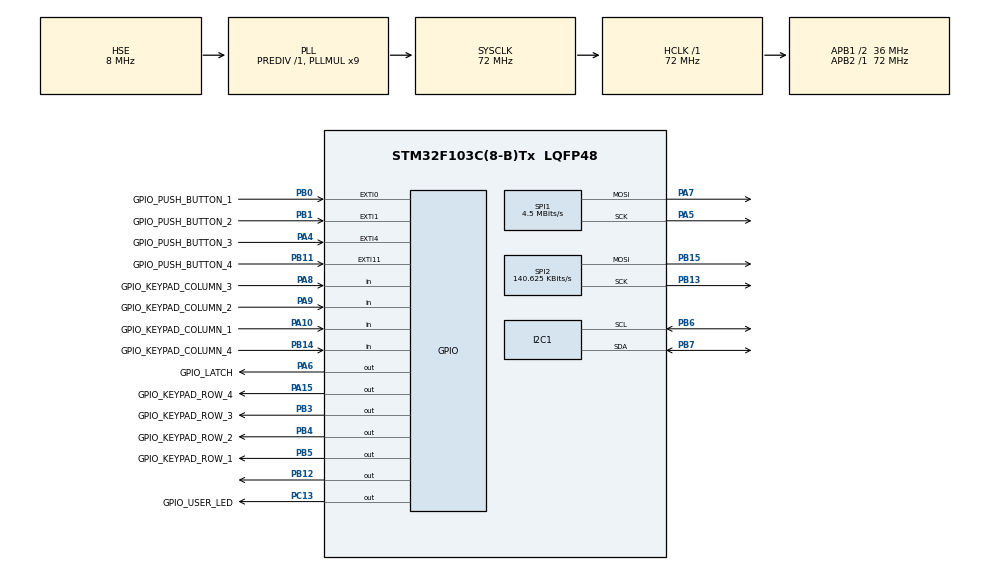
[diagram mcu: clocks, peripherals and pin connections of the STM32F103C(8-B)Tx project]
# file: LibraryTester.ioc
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I2C1.I2C_Mode=I2C_Standard
Mcu.Family=STM32F1
Mcu.Name=STM32F103C(8-B)Tx
Mcu.Package=LQFP48
NVIC.EXTI0_IRQn=true\:0\:0\:false\:false\:true\:true\:true
NVIC.EXTI15_10_IRQn=true\:0\:0\:false\:false\:true\:true\:true
NVIC.EXTI1_IRQn=true\:0\:0\:false\:false\:true\:true\:true
NVIC.EXTI4_IRQn=true\:0\:0\:false\:false\:true\:true\:true
NVIC.PriorityGroup=NVIC_PRIORITYGROUP_4
PA10.GPIO_Label=GPIO_KEYPAD_COLUMN_1
PA10.Signal=GPIO_Input
PA13.Mode=Serial_Wire
PA13.Signal=SYS_JTMS-SWDIO
PA14.Mode=Serial_Wire
PA14.Signal=SYS_JTCK-SWCLK
PA15.GPIO_Label=GPIO_KEYPAD_ROW_4
PA15.GPIO_Speed=GPIO_SPEED_FREQ_HIGH
PA15.Signal=GPIO_Output
PA4.GPIO_Label=GPIO_PUSH_BUTTON_3
PA4.GPIO_ModeDefaultEXTI=GPIO_MODE_IT_RISING_FALLING
PA4.Signal=GPXTI4
PA5.Mode=TX_Only_Simplex_Unidirect_Master
PA5.Signal=SPI1_SCK
PA6.GPIO_Label=GPIO_LATCH
PA6.Signal=GPIO_Output
PA7.Mode=TX_Only_Simplex_Unidirect_Master
PA7.Signal=SPI1_MOSI
PA8.GPIO_Label=GPIO_KEYPAD_COLUMN_3
PA8.Signal=GPIO_Input
PA9.GPIO_Label=GPIO_KEYPAD_COLUMN_2
PA9.Signal=GPIO_Input
PB0.GPIO_Label=GPIO_PUSH_BUTTON_1
PB0.GPIO_ModeDefaultEXTI=GPIO_MODE_IT_RISING_FALLING
PB0.GPIO_PuPd=GPIO_PULLDOWN
PB0.Signal=GPXTI0
PB1.GPIO_Label=GPIO_PUSH_BUTTON_2
PB1.GPIO_ModeDefaultEXTI=GPIO_MODE_IT_RISING_FALLING
PB1.GPIO_PuPd=GPIO_PULLDOWN
PB1.Signal=GPXTI1
PB11.GPIO_Label=GPIO_PUSH_BUTTON_4
PB11.GPIO_ModeDefaultEXTI=GPIO_MODE_IT_RISING_FALLING
PB11.GPIO_PuPd=GPIO_PULLDOWN
PB11.Signal=GPXTI11
PB12.Signal=GPIO_Output
PB13.Mode=TX_Only_Simplex_Unidirect_Master
PB13.Signal=SPI2_SCK
PB14.GPIO_Label=GPIO_KEYPAD_COLUMN_4
PB14.Signal=GPIO_Input
PB15.Mode=TX_Only_Simplex_Unidirect_Master
PB15.Signal=SPI2_MOSI
PB3.GPIO_Label=GPIO_KEYPAD_ROW_3
PB3.GPIO_Speed=GPIO_SPEED_FREQ_HIGH
PB3.Signal=GPIO_Output
PB4.GPIO_Label=GPIO_KEYPAD_ROW_2
PB4.GPIO_Speed=GPIO_SPEED_FREQ_HIGH
PB4.Signal=GPIO_Output
PB5.GPIO_Label=GPIO_KEYPAD_ROW_1
PB5.GPIO_Speed=GPIO_SPEED_FREQ_HIGH
PB5.Signal=GPIO_Output
PB6.Mode=I2C
PB6.Signal=I2C1_SCL
PB7.Mode=I2C
PB7.Signal=I2C1_SDA
PC13-TAMPER-RTC.GPIO_Label=GPIO_USER_LED
PC13-TAMPER-RTC.Signal=GPIO_Output
PD0-OSC_IN.Mode=HSE-External-Oscillator
PD0-OSC_IN.Signal=RCC_OSC_IN
PD1-OSC_OUT.Mode=HSE-External-Oscillator
PD1-OSC_OUT.Signal=RCC_OSC_OUT
ProjectManager.HeapSize=0x200
ProjectManager.StackSize=0x400
ProjectManager.TargetToolchain=STM32CubeIDE
RCC.AHBFreq_Value=72000000
RCC.APB1CLKDivider=RCC_HCLK_DIV2
RCC.APB1Freq_Value=36000000
RCC.APB1TimFreq_Value=72000000
RCC.APB2Freq_Value=72000000
RCC.APB2TimFreq_Value=72000000
RCC.HCLKFreq_Value=72000000
RCC.PLLMUL=RCC_PLL_MUL9
RCC.PLLSourceVirtual=RCC_PLLSOURCE_HSE
RCC.SYSCLKFreq_VALUE=72000000
RCC.SYSCLKSource=RCC_SYSCLKSOURCE_PLLCLK
RCC.USBFreq_Value=72000000
SPI1.BaudRatePrescaler=SPI_BAUDRATEPRESCALER_16
SPI1.CalculateBaudRate=4.5 MBits/s
SPI1.Direction=SPI_DIRECTION_2LINES
SPI1.Mode=SPI_MODE_MASTER
SPI1.VirtualType=VM_MASTER
SPI2.BaudRatePrescaler=SPI_BAUDRATEPRESCALER_256
SPI2.CalculateBaudRate=140.625 KBits/s
SPI2.Direction=SPI_DIRECTION_2LINES
SPI2.Mode=SPI_MODE_MASTER
SPI2.VirtualType=VM_MASTER
board=custom

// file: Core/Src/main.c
/* USER CODE BEGIN Header */
/**
  ******************************************************************************
  * @file           : main.c
  * @brief          : Main program body
  ******************************************************************************
  * @attention
  *
  * <h2><center>&copy; Copyright (c) 2020 STMicroelectronics.
  * All rights reserved.</center></h2>
  *
  * This software component is licensed by ST under BSD 3-Clause license,
  * the "License"; You may not use this file except in compliance with the
  * License. You may obtain a copy of the License at:
  *                        opensource.org/licenses/BSD-3-Clause
  *
  ******************************************************************************
  */
/* USER CODE END Header */

#include "main.h"

I2C_HandleTypeDef hi2c1;

SPI_HandleTypeDef hspi1;
SPI_HandleTypeDef hspi2;

void SystemClock_Config(void);
static void MX_GPIO_Init(void);
static void MX_I2C1_Init(void);
static void MX_SPI1_Init(void);
static void MX_SPI2_Init(void);
/* USER CODE BEGIN PFP */

void MyInit();
int  MyMain();

/* USER CODE END PFP */

int main(void)
{

  /* MCU Configuration--------------------------------------------------------*/

  /* Reset of all peripherals, Initializes the Flash interface and the Systick. */
  HAL_Init();

  /* Configure the system clock */
  SystemClock_Config();

  /* Initialize all configured peripherals */
  MX_GPIO_Init();
  MX_I2C1_Init();
  MX_SPI1_Init();
  MX_SPI2_Init();

  /* Infinite loop */
  /* USER CODE BEGIN WHILE */
  MyInit();
  while (1)
  {
     MyMain();
    /* USER CODE END WHILE */

  }
}

void SystemClock_Config(void)
{
  RCC_OscInitTypeDef RCC_OscInitStruct = {0};
  RCC_ClkInitTypeDef RCC_ClkInitStruct = {0};

  /** Initializes the CPU, AHB and APB busses clocks
  */
  RCC_OscInitStruct.OscillatorType = RCC_OSCILLATORTYPE_HSE;
  RCC_OscInitStruct.HSEState = RCC_HSE_ON;
  RCC_OscInitStruct.HSEPredivValue = RCC_HSE_PREDIV_DIV1;
  RCC_OscInitStruct.HSIState = RCC_HSI_ON;
  RCC_OscInitStruct.PLL.PLLState = RCC_PLL_ON;
  RCC_OscInitStruct.PLL.PLLSource = RCC_PLLSOURCE_HSE;
  RCC_OscInitStruct.PLL.PLLMUL = RCC_PLL_MUL9;
  if (HAL_RCC_OscConfig(&RCC_OscInitStruct) != HAL_OK)
  {
    Error_Handler();
  }
  /** Initializes the CPU, AHB and APB busses clocks
  */
  RCC_ClkInitStruct.ClockType = RCC_CLOCKTYPE_HCLK|RCC_CLOCKTYPE_SYSCLK
                              |RCC_CLOCKTYPE_PCLK1|RCC_CLOCKTYPE_PCLK2;
  RCC_ClkInitStruct.SYSCLKSource = RCC_SYSCLKSOURCE_PLLCLK;
  RCC_ClkInitStruct.AHBCLKDivider = RCC_SYSCLK_DIV1;
  RCC_ClkInitStruct.APB1CLKDivider = RCC_HCLK_DIV2;
  RCC_ClkInitStruct.APB2CLKDivider = RCC_HCLK_DIV1;

  if (HAL_RCC_ClockConfig(&RCC_ClkInitStruct, FLASH_LATENCY_2) != HAL_OK)
  {
    Error_Handler();
  }
}

static void MX_I2C1_Init(void)
{

  hi2c1.Instance = I2C1;
  hi2c1.Init.ClockSpeed = 100000;
  hi2c1.Init.DutyCycle = I2C_DUTYCYCLE_2;
  hi2c1.Init.OwnAddress1 = 0;
  hi2c1.Init.AddressingMode = I2C_ADDRESSINGMODE_7BIT;
  hi2c1.Init.DualAddressMode = I2C_DUALADDRESS_DISABLE;
  hi2c1.Init.OwnAddress2 = 0;
  hi2c1.Init.GeneralCallMode = I2C_GENERALCALL_DISABLE;
  hi2c1.Init.NoStretchMode = I2C_NOSTRETCH_DISABLE;
  if (HAL_I2C_Init(&hi2c1) != HAL_OK)
  {
    Error_Handler();
  }

}

static void MX_SPI1_Init(void)
{

  /* SPI1 parameter configuration*/
  hspi1.Instance = SPI1;
  hspi1.Init.Mode = SPI_MODE_MASTER;
  hspi1.Init.Direction = SPI_DIRECTION_2LINES;
  hspi1.Init.DataSize = SPI_DATASIZE_8BIT;
  hspi1.Init.CLKPolarity = SPI_POLARITY_LOW;
  hspi1.Init.CLKPhase = SPI_PHASE_1EDGE;
  hspi1.Init.NSS = SPI_NSS_SOFT;
  hspi1.Init.BaudRatePrescaler = SPI_BAUDRATEPRESCALER_16;
  hspi1.Init.FirstBit = SPI_FIRSTBIT_MSB;
  hspi1.Init.TIMode = SPI_TIMODE_DISABLE;
  hspi1.Init.CRCCalculation = SPI_CRCCALCULATION_DISABLE;
  hspi1.Init.CRCPolynomial = 10;
  if (HAL_SPI_Init(&hspi1) != HAL_OK)
  {
    Error_Handler();
  }

}

static void MX_SPI2_Init(void)
{

  /* SPI2 parameter configuration*/
  hspi2.Instance = SPI2;
  hspi2.Init.Mode = SPI_MODE_MASTER;
  hspi2.Init.Direction = SPI_DIRECTION_2LINES;
  hspi2.Init.DataSize = SPI_DATASIZE_8BIT;
  hspi2.Init.CLKPolarity = SPI_POLARITY_LOW;
  hspi2.Init.CLKPhase = SPI_PHASE_1EDGE;
  hspi2.Init.NSS = SPI_NSS_SOFT;
  hspi2.Init.BaudRatePrescaler = SPI_BAUDRATEPRESCALER_256;
  hspi2.Init.FirstBit = SPI_FIRSTBIT_MSB;
  hspi2.Init.TIMode = SPI_TIMODE_DISABLE;
  hspi2.Init.CRCCalculation = SPI_CRCCALCULATION_DISABLE;
  hspi2.Init.CRCPolynomial = 10;
  if (HAL_SPI_Init(&hspi2) != HAL_OK)
  {
    Error_Handler();
  }

}

static void MX_GPIO_Init(void)
{
  GPIO_InitTypeDef GPIO_InitStruct = {0};

  /* GPIO Ports Clock Enable */
  __HAL_RCC_GPIOC_CLK_ENABLE();
  __HAL_RCC_GPIOD_CLK_ENABLE();
  __HAL_RCC_GPIOA_CLK_ENABLE();
  __HAL_RCC_GPIOB_CLK_ENABLE();

  /*Configure GPIO pin Output Level */
  HAL_GPIO_WritePin(GPIO_USER_LED_GPIO_Port, GPIO_USER_LED_Pin, GPIO_PIN_RESET);

  /*Configure GPIO pin Output Level */
  HAL_GPIO_WritePin(GPIOA, GPIO_LATCH_Pin|GPIO_KEYPAD_ROW_4_Pin, GPIO_PIN_RESET);

  /*Configure GPIO pin Output Level */
  HAL_GPIO_WritePin(GPIOB, GPIO_PIN_12|GPIO_KEYPAD_ROW_3_Pin|GPIO_KEYPAD_ROW_2_Pin|GPIO_KEYPAD_ROW_1_Pin, GPIO_PIN_RESET);

  /*Configure GPIO pin : GPIO_USER_LED_Pin */
  GPIO_InitStruct.Pin = GPIO_USER_LED_Pin;
  GPIO_InitStruct.Mode = GPIO_MODE_OUTPUT_PP;
  GPIO_InitStruct.Pull = GPIO_NOPULL;
  GPIO_InitStruct.Speed = GPIO_SPEED_FREQ_LOW;
  HAL_GPIO_Init(GPIO_USER_LED_GPIO_Port, &GPIO_InitStruct);

  /*Configure GPIO pin : GPIO_PUSH_BUTTON_3_Pin */
  GPIO_InitStruct.Pin = GPIO_PUSH_BUTTON_3_Pin;
  GPIO_InitStruct.Mode = GPIO_MODE_IT_RISING_FALLING;
  GPIO_InitStruct.Pull = GPIO_NOPULL;
  HAL_GPIO_Init(GPIO_PUSH_BUTTON_3_GPIO_Port, &GPIO_InitStruct);

  /*Configure GPIO pin : GPIO_LATCH_Pin */
  GPIO_InitStruct.Pin = GPIO_LATCH_Pin;
  GPIO_InitStruct.Mode = GPIO_MODE_OUTPUT_PP;
  GPIO_InitStruct.Pull = GPIO_NOPULL;
  GPIO_InitStruct.Speed = GPIO_SPEED_FREQ_LOW;
  HAL_GPIO_Init(GPIO_LATCH_GPIO_Port, &GPIO_InitStruct);

  /*Configure GPIO pins : GPIO_PUSH_BUTTON_1_Pin GPIO_PUSH_BUTTON_2_Pin GPIO_PUSH_BUTTON_4_Pin */
  GPIO_InitStruct.Pin = GPIO_PUSH_BUTTON_1_Pin|GPIO_PUSH_BUTTON_2_Pin|GPIO_PUSH_BUTTON_4_Pin;
  GPIO_InitStruct.Mode = GPIO_MODE_IT_RISING_FALLING;
  GPIO_InitStruct.Pull = GPIO_PULLDOWN;
  HAL_GPIO_Init(GPIOB, &GPIO_InitStruct);

  /*Configure GPIO pin : PB12 */
  GPIO_InitStruct.Pin = GPIO_PIN_12;
  GPIO_InitStruct.Mode = GPIO_MODE_OUTPUT_PP;
  GPIO_InitStruct.Pull = GPIO_NOPULL;
  GPIO_InitStruct.Speed = GPIO_SPEED_FREQ_LOW;
  HAL_GPIO_Init(GPIOB, &GPIO_InitStruct);

  /*Configure GPIO pin : GPIO_KEYPAD_COLUMN_4_Pin */
  GPIO_InitStruct.Pin = GPIO_KEYPAD_COLUMN_4_Pin;
  GPIO_InitStruct.Mode = GPIO_MODE_INPUT;
  GPIO_InitStruct.Pull = GPIO_NOPULL;
  HAL_GPIO_Init(GPIO_KEYPAD_COLUMN_4_GPIO_Port, &GPIO_InitStruct);

  /*Configure GPIO pins : GPIO_KEYPAD_COLUMN_3_Pin GPIO_KEYPAD_COLUMN_2_Pin GPIO_KEYPAD_COLUMN_1_Pin */
  GPIO_InitStruct.Pin = GPIO_KEYPAD_COLUMN_3_Pin|GPIO_KEYPAD_COLUMN_2_Pin|GPIO_KEYPAD_COLUMN_1_Pin;
  GPIO_InitStruct.Mode = GPIO_MODE_INPUT;
  GPIO_InitStruct.Pull = GPIO_NOPULL;
  HAL_GPIO_Init(GPIOA, &GPIO_InitStruct);

  /*Configure GPIO pin : GPIO_KEYPAD_ROW_4_Pin */
  GPIO_InitStruct.Pin = GPIO_KEYPAD_ROW_4_Pin;
  GPIO_InitStruct.Mode = GPIO_MODE_OUTPUT_PP;
  GPIO_InitStruct.Pull = GPIO_NOPULL;
  GPIO_InitStruct.Speed = GPIO_SPEED_FREQ_HIGH;
  HAL_GPIO_Init(GPIO_KEYPAD_ROW_4_GPIO_Port, &GPIO_InitStruct);

  /*Configure GPIO pins : GPIO_KEYPAD_ROW_3_Pin GPIO_KEYPAD_ROW_2_Pin GPIO_KEYPAD_ROW_1_Pin */
  GPIO_InitStruct.Pin = GPIO_KEYPAD_ROW_3_Pin|GPIO_KEYPAD_ROW_2_Pin|GPIO_KEYPAD_ROW_1_Pin;
  GPIO_InitStruct.Mode = GPIO_MODE_OUTPUT_PP;
  GPIO_InitStruct.Pull = GPIO_NOPULL;
  GPIO_InitStruct.Speed = GPIO_SPEED_FREQ_HIGH;
  HAL_GPIO_Init(GPIOB, &GPIO_InitStruct);

  /* EXTI interrupt init*/
  HAL_NVIC_SetPriority(EXTI0_IRQn, 0, 0);
  HAL_NVIC_EnableIRQ(EXTI0_IRQn);

  HAL_NVIC_SetPriority(EXTI1_IRQn, 0, 0);
  HAL_NVIC_EnableIRQ(EXTI1_IRQn);

  HAL_NVIC_SetPriority(EXTI4_IRQn, 0, 0);
  HAL_NVIC_EnableIRQ(EXTI4_IRQn);

  HAL_NVIC_SetPriority(EXTI15_10_IRQn, 0, 0);
  HAL_NVIC_EnableIRQ(EXTI15_10_IRQn);

}

void Error_Handler(void)
{
}

/************************ (C) COPYRIGHT STMicroelectronics *****END OF FILE****/
